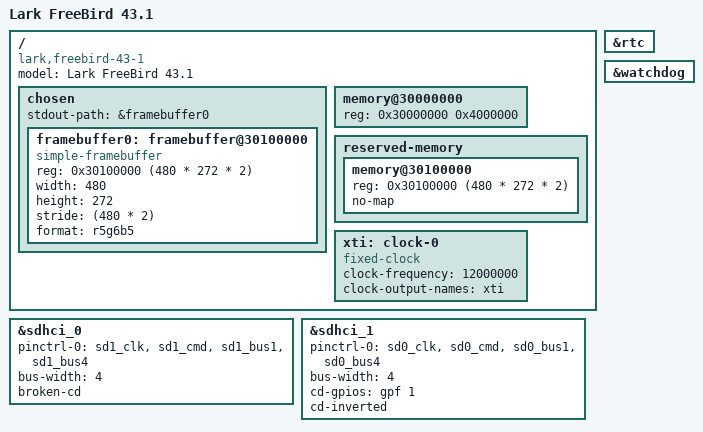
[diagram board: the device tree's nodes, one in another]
// SPDX-License-Identifier: GPL-2.0

/dts-v1/;
#include "s3c2416.dtsi"

/ {
	model = "Lark FreeBird 43.1";
	compatible = "lark,freebird-43-1", "samsung,s3c2416";

	chosen {
		stdout-path = &framebuffer0;
		#address-cells = <1>;
		#size-cells = <1>;
		ranges;

		framebuffer0: framebuffer@30100000 {
			compatible = "simple-framebuffer";
			reg = <0x30100000 (480 * 272 * 2)>;
			width = <480>;
			height = <272>;
			stride = <(480 * 2)>;
			format = "r5g6b5";
		};
	};

	memory@30000000 {
		device_type = "memory";
		reg =  <0x30000000 0x4000000>;
	};

	reserved-memory {
		#address-cells = <1>;
		#size-cells = <1>;
		ranges;

		memory@30100000 {
			reg = <0x30100000 (480 * 272 * 2)>;
			no-map;
		};
	};

	xti: clock-0 {
		compatible = "fixed-clock";
		clock-frequency = <12000000>;
		clock-output-names = "xti";
		#clock-cells = <0>;
	};
};

&rtc {
	status = "okay";
};

&sdhci_0 {
	pinctrl-names = "default";
	pinctrl-0 = <&sd1_clk>, <&sd1_cmd>,
			<&sd1_bus1>, <&sd1_bus4>;
	bus-width = <4>;
	broken-cd;
	status = "okay";
};

&sdhci_1 {
	pinctrl-names = "default";
	pinctrl-0 = <&sd0_clk>, <&sd0_cmd>,
			<&sd0_bus1>, <&sd0_bus4>;
	bus-width = <4>;
	cd-gpios = <&gpf 1 0>;
	cd-inverted;
	status = "okay";
};

&watchdog {
	status = "okay";
};
